VERSION ""

NS_ :

BS_:

BU_:

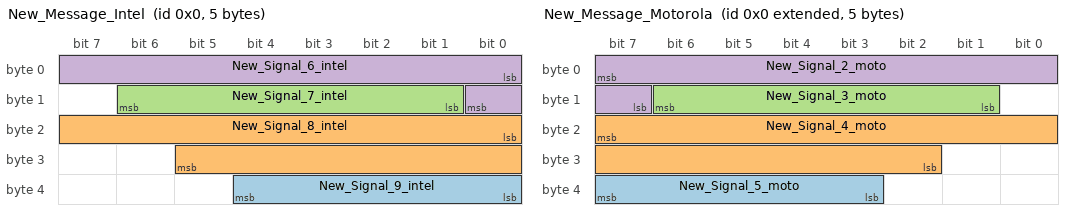
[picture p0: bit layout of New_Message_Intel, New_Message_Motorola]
BO_ 0 New_Message_Intel: 5 Vector__XXX
 SG_ New_Signal_9_intel : 32|5@1+ (1,0) [0|31] "" Vector__XXX
 SG_ New_Signal_8_intel : 16|14@1+ (1,0) [0|16383] "" Vector__XXX
 SG_ New_Signal_7_intel : 9|6@1+ (1,0) [0|63] "" Vector__XXX
 SG_ New_Signal_6_intel : 0|9@1+ (1,0) [0|511] "" Vector__XXX

BO_ 2147483648 New_Message_Motorola: 5 Vector__XXX
 SG_ New_Signal_5_moto : 39|5@0+ (1,0) [0|31] "" Vector__XXX
 SG_ New_Signal_4_moto : 23|14@0+ (1,0) [0|16383] "" Vector__XXX
 SG_ New_Signal_3_moto : 14|6@0+ (1,0) [0|63] "" Vector__XXX
 SG_ New_Signal_2_moto : 7|9@0+ (1,0) [0|255] "" Vector__XXX

BA_DEF_ BO_  "CANFD_BRS" ENUM  "0","1";
BA_DEF_  "DBName" STRING ;
BA_DEF_  "BusType" STRING ;
BA_DEF_ BO_  "VFrameFormat" ENUM  "StandardCAN","ExtendedCAN","reserved","reserved","reserved","reserved","reserved","reserved","reserved","reserved","reserved","reserved","reserved","reserved","StandardCAN_FD","ExtendedCAN_FD";
BA_DEF_DEF_  "CANFD_BRS" "1";
BA_DEF_DEF_  "DBName" "";
BA_DEF_DEF_  "BusType" "";
BA_DEF_DEF_  "VFrameFormat" "StandardCAN";
BA_ "BusType" "CAN FD";
BA_ "DBName" "CANdb_FD";
BA_ "VFrameFormat" BO_ 2147483648 1;
